AUTOSAR XML (schema 314)
package /ComponentType
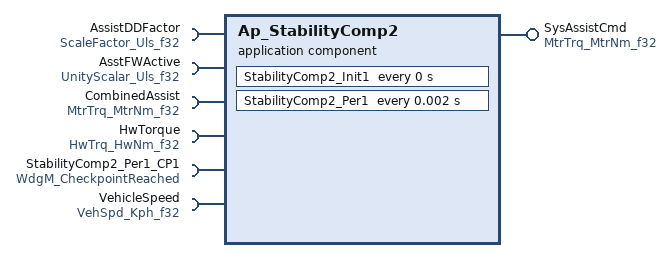
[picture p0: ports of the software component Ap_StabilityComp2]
  application software component type Ap_StabilityComp2
    provide port SysAssistCmd: unqueued-sender-com-spec{data-element=MtrNm_f32, can-invalidate=false, init-value=D_ZERO_ULS_F32}, provided-interface=MtrTrq_MtrNm_f32
    6 x require port:
      AssistDDFactor: unqueued-receiver-com-spec{data-element=Uls_f32, init-value=D_ONE_ULS_F32}, required-interface=ScaleFactor_Uls_f32
      AsstFWActive: unqueued-receiver-com-spec{data-element=Uls_f32, init-value=D_ZERO_ULS_F32}, required-interface=UnityScalar_Uls_f32
      CombinedAssist: unqueued-receiver-com-spec{data-element=MtrNm_f32, init-value=D_ZERO_ULS_F32}, required-interface=MtrTrq_MtrNm_f32
      HwTorque: unqueued-receiver-com-spec{data-element=HwNm_f32, init-value=D_ZERO_ULS_F32}, required-interface=HwTrq_HwNm_f32
      StabilityComp2_Per1_CP1: client-com-spec=CheckpointReached, required-interface=WdgM_CheckpointReached
      VehicleSpeed: unqueued-receiver-com-spec{data-element=Kph_f32, init-value=D_ZERO_ULS_F32}, required-interface=VehSpd_Kph_f32
  internal behavior Ap_StabilityComp2_InternalBehavior: component=Ap_StabilityComp2
    timing event StabilityComp2_Init1_InitEvent: start-on-event=StabilityComp2_Init1, period=0
    timing event TMT_StabilityComp2_Per1: start-on-event=StabilityComp2_Per1, period=0.002
    port-api-options:
      enable-take-address=false, indirect-api=false, port=AssistDDFactor
      enable-take-address=false, indirect-api=false, port=AsstFWActive
      enable-take-address=false, indirect-api=false, port=CombinedAssist
      enable-take-address=false, indirect-api=false, port=HwTorque
      enable-take-address=false, indirect-api=false, port=StabilityComp2_Per1_CP1
      enable-take-address=false, indirect-api=false, port=SysAssistCmd
      enable-take-address=false, indirect-api=false, port=VehicleSpeed
    runnable StabilityComp2_Init1
    runnable StabilityComp2_Per1
      5 x data read access:
        READ_AssistDDFactor_Uls_f32: data-element=AssistDDFactor.Uls_f32
        READ_AsstFWActive_Uls_f32: data-element=AsstFWActive.Uls_f32
        READ_CombinedAssist_MtrNm_f32: data-element=CombinedAssist.MtrNm_f32
        READ_HwTorque_HwNm_f32: data-element=HwTorque.HwNm_f32
        READ_VehicleSpeed_Kph_f32: data-element=VehicleSpeed.Kph_f32
      data write access WRITE_SysAssistCmd_MtrNm_f32: data-element=SysAssistCmd.MtrNm_f32
      sync call SC_StabilityComp2_Per1_CP1_CheckpointReached: operation=StabilityComp2_Per1_CP1.CheckpointReached, timeout=0
  swc implementation Ap_StabilityComp2_Implementation: behavior=Ap_StabilityComp2_InternalBehavior
    code-descriptors:
      code Code: type=SRC
